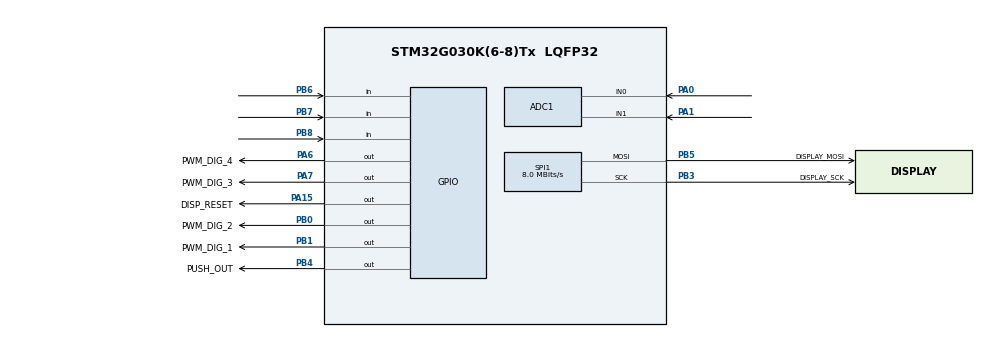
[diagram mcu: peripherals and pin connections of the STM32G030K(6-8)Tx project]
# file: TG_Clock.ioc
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ADC1.Channel-0\#ChannelRegularConversion=ADC_CHANNEL_0
ADC1.NbrOfConversionFlag=1
ADC1.Rank-0\#ChannelRegularConversion=1
ADC1.SamplingTime-0\#ChannelRegularConversion=ADC_SAMPLINGTIME_COMMON_1
ADC1.SelectedChannel=ADC_CHANNEL_0|ADC_CHANNEL_1
ADC1.master=1
Mcu.Family=STM32G0
Mcu.Name=STM32G030K(6-8)Tx
Mcu.Package=LQFP32
NVIC.SPI1_IRQn=true\:0\:0\:false\:false\:true\:true\:true\:true
PA0.Mode=IN0
PA0.Signal=ADC1_IN0
PA1.Mode=IN1
PA1.Signal=ADC1_IN1
PA13.Mode=Serial_Wire
PA13.Signal=SYS_SWDIO
PA14-BOOT0.Mode=Serial_Wire
PA14-BOOT0.Signal=SYS_SWCLK
PA15.GPIO_Label=DISP_RESET
PA15.Signal=GPIO_Output
PA6.GPIO_Label=PWM_DIG_4
PA6.Signal=GPIO_Output
PA7.GPIO_Label=PWM_DIG_3
PA7.Signal=GPIO_Output
PB0.GPIO_Label=PWM_DIG_2
PB0.Signal=GPIO_Output
PB1.GPIO_Label=PWM_DIG_1
PB1.Signal=GPIO_Output
PB3.GPIO_Label=DISPLAY_SCK
PB3.Mode=TX_Only_Simplex_Unidirect_Master
PB3.Signal=SPI1_SCK
PB4.GPIO_Label=PUSH_OUT
PB4.Signal=GPIO_Output
PB5.GPIO_Label=DISPLAY_MOSI
PB5.Mode=TX_Only_Simplex_Unidirect_Master
PB5.Signal=SPI1_MOSI
PB6.Signal=GPIO_Input
PB7.Signal=GPIO_Input
PB8.Signal=GPIO_Input
ProjectManager.HeapSize=0x200
ProjectManager.StackSize=0x400
ProjectManager.TargetToolchain=CMake
RCC.ADCFreq_Value=64000000
RCC.AHBFreq_Value=64000000
RCC.CortexFreq_Value=64000000
RCC.EXTERNAL_CLOCK_VALUE=12288000
RCC.HCLKFreq_Value=64000000
RCC.HSE_VALUE=8000000
RCC.HSI_VALUE=16000000
RCC.LSE_VALUE=32768
RCC.SYSCLKFreq_VALUE=64000000
RCC.SYSCLKSource=RCC_SYSCLKSOURCE_PLLCLK
RCC.VCOOutputFreq_Value=128000000
SPI1.BaudRatePrescaler=SPI_BAUDRATEPRESCALER_8
SPI1.CLKPolarity=SPI_POLARITY_LOW
SPI1.CalculateBaudRate=8.0 MBits/s
SPI1.Direction=SPI_DIRECTION_2LINES
SPI1.Mode=SPI_MODE_MASTER
SPI1.VirtualType=VM_MASTER
board=custom

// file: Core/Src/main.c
/* USER CODE BEGIN Header */
/**
  ******************************************************************************
  * @file           : main.c
  * @brief          : Main program body
  ******************************************************************************
  * @attention
  *
  * Copyright (c) 2026 STMicroelectronics.
  * All rights reserved.
  *
  * This software is licensed under terms that can be found in the LICENSE file
  * in the root directory of this software component.
  * If no LICENSE file comes with this software, it is provided AS-IS.
  *
  ******************************************************************************
  */
/* USER CODE END Header */
#include "main.h"
#include "adc.h"
// #include "spi.h"
#include "gpio.h"

void SystemClock_Config(void);

/* USER CODE BEGIN 0 */

void dispResetLow(void)
{
  LL_GPIO_ResetOutputPin(DISPLAY_RESET_GPIO_Port, DISPLAY_RESET_Pin);
}

void dispResetHigh(void)
{
  LL_GPIO_SetOutputPin(DISPLAY_RESET_GPIO_Port, DISPLAY_RESET_Pin);
}

/* USER CODE END 0 */

int main(void)
{

  /* MCU Configuration--------------------------------------------------------*/

  /* Reset of all peripherals, Initializes the Flash interface and the Systick. */
  LL_APB2_GRP1_EnableClock(LL_APB2_GRP1_PERIPH_SYSCFG);
  LL_APB1_GRP1_EnableClock(LL_APB1_GRP1_PERIPH_PWR);

  /* SysTick_IRQn interrupt configuration */
  NVIC_SetPriority(SysTick_IRQn, 3);

  /* Configure the system clock */
  SystemClock_Config();

  /* Initialize all configured peripherals */
  MX_GPIO_Init();
  MX_ADC1_Init();
  MX_SPI1_Init();

  /* Infinite loop */
  while (1)
  {

  }
}

void SystemClock_Config(void)
{
  LL_FLASH_SetLatency(LL_FLASH_LATENCY_2);
  while(LL_FLASH_GetLatency() != LL_FLASH_LATENCY_2)
  {
  }

  /* HSI configuration and activation */
  LL_RCC_HSI_Enable();
  while(LL_RCC_HSI_IsReady() != 1)
  {
  }

  /* Main PLL configuration and activation */
  LL_RCC_PLL_ConfigDomain_SYS(LL_RCC_PLLSOURCE_HSI, LL_RCC_PLLM_DIV_1, 8, LL_RCC_PLLR_DIV_2);
  LL_RCC_PLL_Enable();
  LL_RCC_PLL_EnableDomain_SYS();
  while(LL_RCC_PLL_IsReady() != 1)
  {
  }

  /* Set AHB prescaler*/
  LL_RCC_SetAHBPrescaler(LL_RCC_SYSCLK_DIV_1);

  /* Sysclk activation on the main PLL */
  LL_RCC_SetSysClkSource(LL_RCC_SYS_CLKSOURCE_PLL);
  while(LL_RCC_GetSysClkSource() != LL_RCC_SYS_CLKSOURCE_STATUS_PLL)
  {
  }

  /* Set APB1 prescaler*/
  LL_RCC_SetAPB1Prescaler(LL_RCC_APB1_DIV_1);

  LL_Init1msTick(64000000);

  /* Update CMSIS variable (which can be updated also through SystemCoreClockUpdate function) */
  LL_SetSystemCoreClock(64000000);
}

void Error_Handler(void)
{
  __disable_irq();
  while (1)
  {
  }
}
